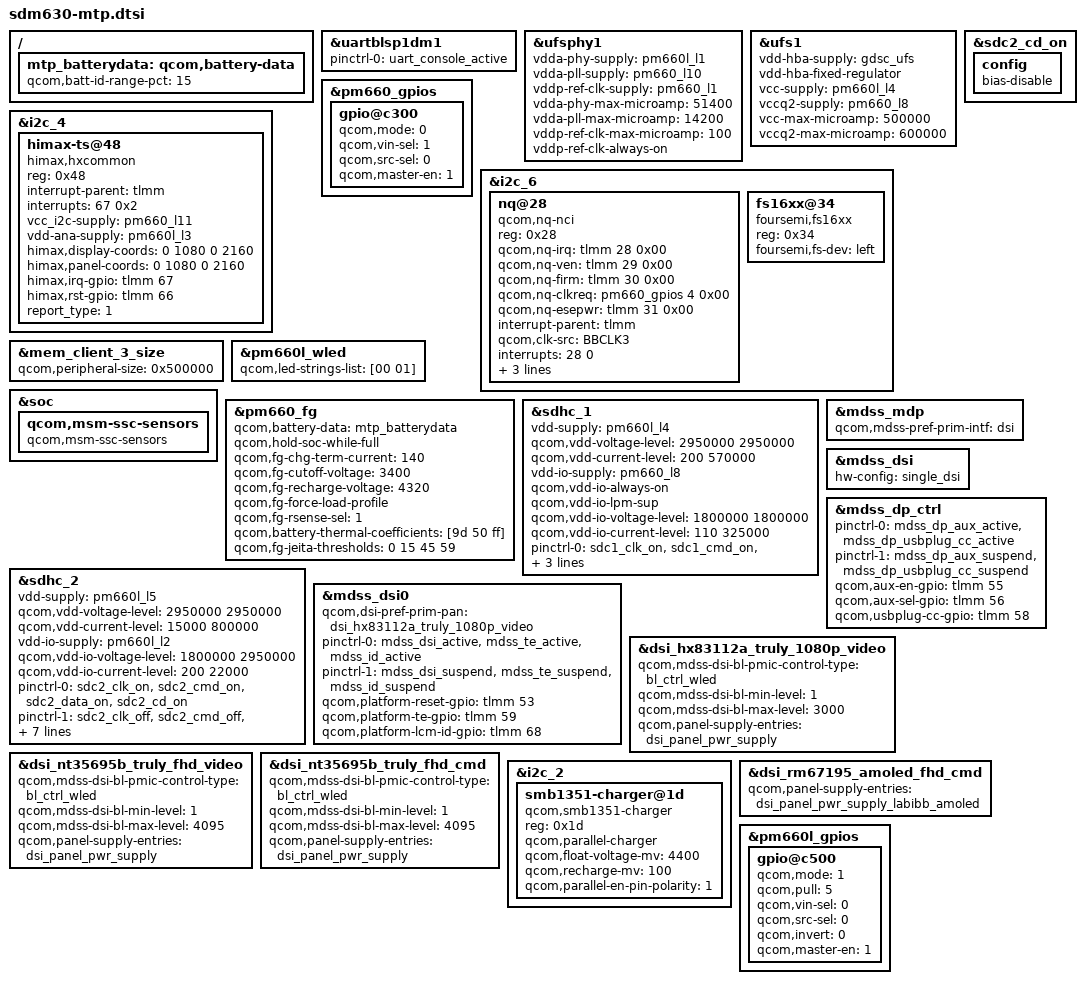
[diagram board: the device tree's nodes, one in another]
/* Copyright (c) 2017, The Linux Foundation. All rights reserved.
 *
 * This program is free software; you can redistribute it and/or modify
 * it under the terms of the GNU General Public License version 2 and
 * only version 2 as published by the Free Software Foundation.
 *
 * This program is distributed in the hope that it will be useful,
 * but WITHOUT ANY WARRANTY; without even the implied warranty of
 * MERCHANTABILITY or FITNESS FOR A PARTICULAR PURPOSE.  See the
 * GNU General Public License for more details.
 */

#include "sdm660-pinctrl.dtsi"
#include "sdm630-camera-sensor-mtp.dtsi"
/ {
	mtp_batterydata: qcom,battery-data {
		qcom,batt-id-range-pct = <15>;
#if 1
		#include "fg-gen3-batterydata-atl-3435mah.dtsi"
		#include "fg-gen3-batterydata-yandexvek-3060mah.dtsi"
#else
		#include "fg-gen3-batterydata-itech-3000mah.dtsi"
		#include "fg-gen3-batterydata-ascent-3450mah.dtsi"
#endif
	};
};

&uartblsp1dm1 {
	status = "ok";
	pinctrl-names = "default";
	pinctrl-0 = <&uart_console_active>;
};

&ufsphy1 {
	vdda-phy-supply = <&pm660l_l1>;
	vdda-pll-supply = <&pm660_l10>;
	vddp-ref-clk-supply = <&pm660_l1>;
	vdda-phy-max-microamp = <51400>;
	vdda-pll-max-microamp = <14200>;
	vddp-ref-clk-max-microamp = <100>;
	vddp-ref-clk-always-on;
	status = "ok";
};

&ufs1 {
	vdd-hba-supply = <&gdsc_ufs>;
	vdd-hba-fixed-regulator;
	vcc-supply = <&pm660l_l4>;
	vccq2-supply = <&pm660_l8>;
	vcc-max-microamp = <500000>;
	vccq2-max-microamp = <600000>;
	status = "ok";
};

&pm660_gpios {
	/* GPIO 4 (NFC_CLK_REQ) */
	gpio@c300 {
		qcom,mode = <0>;
		qcom,vin-sel = <1>;
		qcom,src-sel = <0>;
		qcom,master-en = <1>;
		status = "okay";
	};
};

&i2c_6 { /* BLSP1 QUP6 (NFC) */
	status = "okay";
	nq@28 {
		compatible = "qcom,nq-nci";
		reg = <0x28>;
		qcom,nq-irq = <&tlmm 28 0x00>;
		qcom,nq-ven = <&tlmm 29 0x00>;
		qcom,nq-firm = <&tlmm 30 0x00>;
		qcom,nq-clkreq = <&pm660_gpios 4 0x00>;
		qcom,nq-esepwr = <&tlmm 31 0x00>;
		interrupt-parent = <&tlmm>;
		qcom,clk-src = "BBCLK3";
		interrupts = <28 0>;
		interrupt-names = "nfc_irq";
		pinctrl-names = "nfc_active", "nfc_suspend";
		pinctrl-0 = <&nfc_int_active &nfc_enable_active>;
		pinctrl-1 = <&nfc_int_suspend &nfc_enable_suspend>;
		clocks = <&clock_rpmcc RPM_LN_BB_CLK3_PIN>;
		clock-names = "ref_clk";
	};
	fs16xx@34{
		compatible="foursemi,fs16xx";
		reg=<0x34>;
		foursemi,fs-dev="left";
		status="okay";
	};
};

&i2c_4 {
	status = "okay";
	himax-ts@48 {
		compatible = "himax,hxcommon";
		reg = <0x48>;
		interrupt-parent = <&tlmm>;
		interrupts = <67 0x2>;
		vcc_i2c-supply = <&pm660_l11>;
		vdd-ana-supply = <&pm660l_l3>;
		himax,display-coords = <0 1080 0 2160>;
		himax,panel-coords = <0 1080 0 2160>;
		himax,irq-gpio = <&tlmm 67 0x00>;
		himax,rst-gpio = <&tlmm 66 0x00>;
		report_type = <1>;
	};
};

&mem_client_3_size {
	qcom,peripheral-size = <0x500000>;
};

&pm660l_wled {
	qcom,led-strings-list = [00 01];
};

&soc {
	qcom,msm-ssc-sensors {
		compatible = "qcom,msm-ssc-sensors";
	};
};

&pm660_fg {
	qcom,battery-data = <&mtp_batterydata>;
	qcom,hold-soc-while-full;
	qcom,fg-chg-term-current = <140>;
	qcom,fg-cutoff-voltage = <3400>;
#if 0
	qcom,fg-auto-recharge-soc;
	qcom,fg-recharge-soc-thr = <99>;
#else
	qcom,fg-recharge-voltage = <4320>;
#endif
	qcom,fg-force-load-profile;
	qcom,fg-rsense-sel = <1>;
/*follow 80-vt310-138_b_understanding_pmi8998_fuel_gauge.pdf*/
	qcom,battery-thermal-coefficients = [9d 50 ff];
	qcom,fg-jeita-thresholds = <0 15 45 59>;
};

&sdhc_1 {
	/* device core power supply */
	vdd-supply = <&pm660l_l4>;
	qcom,vdd-voltage-level = <2950000 2950000>;
	qcom,vdd-current-level = <200 570000>;

	/* device communication power supply */
	vdd-io-supply = <&pm660_l8>;
	qcom,vdd-io-always-on;
	qcom,vdd-io-lpm-sup;
	qcom,vdd-io-voltage-level = <1800000 1800000>;
	qcom,vdd-io-current-level = <110 325000>;

	pinctrl-names = "active", "sleep";
	pinctrl-0 = <&sdc1_clk_on &sdc1_cmd_on &sdc1_data_on &sdc1_rclk_on>;
	pinctrl-1 = <&sdc1_clk_off &sdc1_cmd_off &sdc1_data_off &sdc1_rclk_off>;

	status = "ok";
};

&sdc2_cd_on {
	config {
		/delete-property/ bias-pull-up;
		bias-disable;
	};
};

&sdhc_2 {
	/* device core power supply */
	vdd-supply = <&pm660l_l5>;
	qcom,vdd-voltage-level = <2950000 2950000>;
	qcom,vdd-current-level = <15000 800000>;

	/* device communication power supply */
	vdd-io-supply = <&pm660l_l2>;
	qcom,vdd-io-voltage-level = <1800000 2950000>;
	qcom,vdd-io-current-level = <200 22000>;

	pinctrl-names = "active", "sleep";
	pinctrl-0 = <&sdc2_clk_on &sdc2_cmd_on &sdc2_data_on &sdc2_cd_on>;
	pinctrl-1 = <&sdc2_clk_off &sdc2_cmd_off &sdc2_data_off &sdc2_cd_off>;

	#address-cells = <0>;
	interrupt-parent = <&sdhc_2>;
	interrupts = <0 1 2>;
	#interrupt-cells = <1>;
	interrupt-map-mask = <0xffffffff>;
	interrupt-map = <0 &intc 0 0 125 0
			1 &intc 0 0 221 0
			2 &tlmm 54 0>;
	interrupt-names = "hc_irq", "pwr_irq", "status_irq";
	cd-gpios = <&tlmm 54 0x0>;
	status = "ok";
};

&mdss_mdp {
	qcom,mdss-pref-prim-intf = "dsi";
};

&mdss_dsi {
	hw-config = "single_dsi";
};

&mdss_dsi0 {
#if 1
	qcom,dsi-pref-prim-pan = <&dsi_hx83112a_truly_1080p_video>;
#else
	qcom,dsi-pref-prim-pan = <&dsi_nt35695b_truly_fhd_video>;
#endif
	pinctrl-names = "mdss_default", "mdss_sleep";
	pinctrl-0 = <&mdss_dsi_active &mdss_te_active &mdss_id_active>;
	pinctrl-1 = <&mdss_dsi_suspend &mdss_te_suspend &mdss_id_suspend>;
	qcom,platform-reset-gpio = <&tlmm 53 0>;
	qcom,platform-te-gpio = <&tlmm 59 0>;
	qcom,platform-lcm-id-gpio = <&tlmm 68 0>;
};

&mdss_dp_ctrl {
	pinctrl-names = "mdss_dp_active", "mdss_dp_sleep";
	pinctrl-0 = <&mdss_dp_aux_active &mdss_dp_usbplug_cc_active>;
	pinctrl-1 = <&mdss_dp_aux_suspend &mdss_dp_usbplug_cc_suspend>;
	qcom,aux-en-gpio = <&tlmm 55 0>;
	qcom,aux-sel-gpio = <&tlmm 56 0>;
	qcom,usbplug-cc-gpio = <&tlmm 58 0>;
};

&pm660l_wled {
	qcom,led-strings-list = [00 01];
};

&dsi_hx83112a_truly_1080p_video {
	qcom,mdss-dsi-bl-pmic-control-type = "bl_ctrl_wled";
	qcom,mdss-dsi-bl-min-level = <1>;
/*Modify Max backlight brightness begin*/
	qcom,mdss-dsi-bl-max-level = <3000>;
/*Modify Max backlight brightness end*/
	qcom,panel-supply-entries = <&dsi_panel_pwr_supply>;
};
&dsi_nt35695b_truly_fhd_video {
	qcom,mdss-dsi-bl-pmic-control-type = "bl_ctrl_wled";
	qcom,mdss-dsi-bl-min-level = <1>;
	qcom,mdss-dsi-bl-max-level = <4095>;
	qcom,panel-supply-entries = <&dsi_panel_pwr_supply>;
};

&dsi_nt35695b_truly_fhd_cmd {
	qcom,mdss-dsi-bl-pmic-control-type = "bl_ctrl_wled";
	qcom,mdss-dsi-bl-min-level = <1>;
	qcom,mdss-dsi-bl-max-level = <4095>;
	qcom,panel-supply-entries = <&dsi_panel_pwr_supply>;
};

&i2c_2 {
	status = "ok";
	smb1351-charger@1d {
		compatible = "qcom,smb1351-charger";
		reg = <0x1d>;
		qcom,parallel-charger;
		qcom,float-voltage-mv = <4400>;
		qcom,recharge-mv = <100>;
		qcom,parallel-en-pin-polarity = <1>;
	};
};

&dsi_rm67195_amoled_fhd_cmd {
	qcom,panel-supply-entries = <&dsi_panel_pwr_supply_labibb_amoled>;
};
&pm660l_gpios {
	/* GPIO 6 for fps poewr enable pin */
	gpio@c500 {
		qcom,mode = <1>;                /* Output */
		qcom,pull = <5>;                /* No Pull */
		qcom,vin-sel = <0>;             /* VIN1 GPIO_LV */
		qcom,src-sel = <0>;             /* GPIO */
		qcom,invert = <0>;              /* Invert */
		qcom,master-en = <1>;           /* Enable GPIO */
		status = "ok";
	};
};
